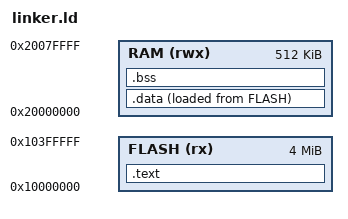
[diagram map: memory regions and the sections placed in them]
ENTRY(Reset_Handler)

MEMORY
{
  FLASH (rx)  : ORIGIN = 0x10000000, LENGTH = 4M
  RAM (rwx)   : ORIGIN = 0x20000000, LENGTH = 512K
}

_estack = ORIGIN(RAM) + LENGTH(RAM);

SECTIONS
{
  .text :
  {
    KEEP(*(.isr_vector))
    KEEP(*(.picobin_block))
    *(.text*)
    *(.rodata*)
  } > FLASH

  .data :
  {
    _sdata = .;
    *(.data*)
    _edata = .;
  } > RAM AT> FLASH

  _sidata = LOADADDR(.data);

  .bss (NOLOAD) :
  {
    _sbss = .;
    *(.bss*)
    *(COMMON)
    _ebss = .;
  } > RAM
}
